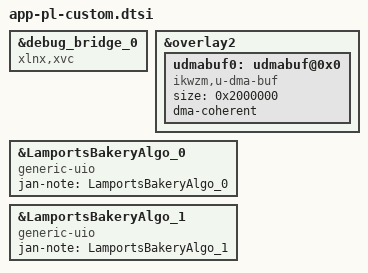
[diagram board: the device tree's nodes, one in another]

&debug_bridge_0 {
    compatible = "xlnx,xvc";
};

&overlay2 {
    udmabuf0: udmabuf@0x0 {
        compatible = "ikwzm,u-dma-buf";
        size = <0x2000000>;
        dma-coherent;
    };
};

&LamportsBakeryAlgo_0 {
    compatible = "generic-uio";
    jan-note = "LamportsBakeryAlgo_0";
};

&LamportsBakeryAlgo_1 {
    compatible = "generic-uio";
    jan-note = "LamportsBakeryAlgo_1";
};

